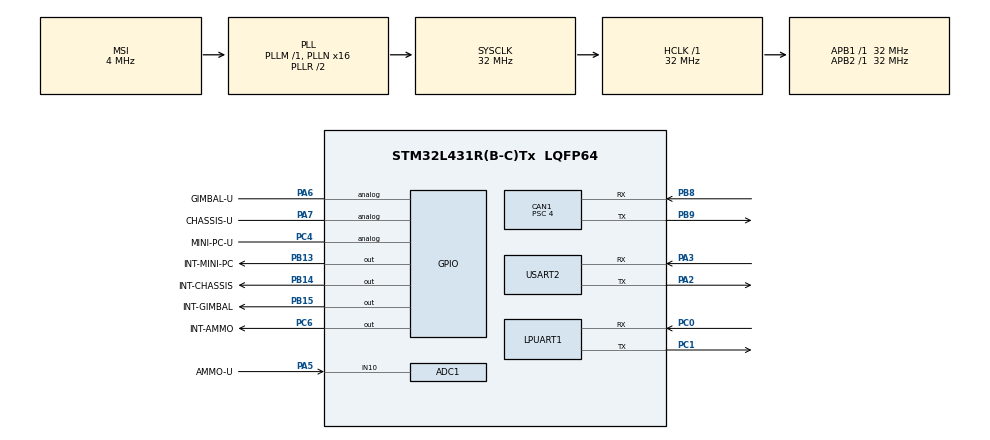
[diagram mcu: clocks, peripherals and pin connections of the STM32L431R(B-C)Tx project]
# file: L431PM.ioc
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ADC1.Channel-4\#ChannelRegularConversion=ADC_CHANNEL_10
ADC1.EOCSelection=ADC_EOC_SINGLE_CONV
ADC1.NbrOfConversionFlag=1
ADC1.OffsetNumber-4\#ChannelRegularConversion=ADC_OFFSET_NONE
ADC1.Rank-4\#ChannelRegularConversion=1
ADC1.SamplingTime-4\#ChannelRegularConversion=ADC_SAMPLETIME_47CYCLES_5
ADC1.master=1
CAN1.BS1=CAN_BS1_13TQ
CAN1.BS2=CAN_BS2_2TQ
CAN1.CalculateBaudRate=500000
CAN1.CalculateTimeBit=2000
CAN1.CalculateTimeQuantum=125.0
CAN1.Prescaler=4
Mcu.Family=STM32L4
Mcu.Name=STM32L431R(B-C)Tx
Mcu.Package=LQFP64
NVIC.ADC1_2_IRQn=true\:4\:0\:false\:false\:true\:true\:true\:true
NVIC.PriorityGroup=NVIC_PRIORITYGROUP_4
PB8.Mode=CAN_Activate
PB8.Signal=CAN1_RX
PB9.Mode=CAN_Activate
PB9.Signal=CAN1_TX
PA13\ (JTMS-SWDIO).Mode=Serial_Wire
PA13\ (JTMS-SWDIO).Signal=SYS_JTMS-SWDIO
PA14\ (JTCK-SWCLK).Mode=Serial_Wire
PA14\ (JTCK-SWCLK).Signal=SYS_JTCK-SWCLK
PA2.Mode=Asynchronous
PA2.Signal=USART2_TX
PA3.Mode=Asynchronous
PA3.Signal=USART2_RX
PA5.GPIO_Label=AMMO-U
PA5.Signal=ADCx_IN10
PA6.GPIO_Label=GIMBAL-U
PA6.Signal=GPIO_Analog
PA7.GPIO_Label=CHASSIS-U
PA7.Signal=GPIO_Analog
PB13.GPIO_Label=INT-MINI-PC
PB13.GPIO_State=GPIO_PIN_SET
PB13.Signal=GPIO_Output
PB14.GPIO_Label=INT-CHASSIS
PB14.GPIO_State=GPIO_PIN_SET
PB14.Signal=GPIO_Output
PB15.GPIO_Label=INT-GIMBAL
PB15.GPIO_State=GPIO_PIN_SET
PB15.Signal=GPIO_Output
PC0.Mode=Asynchronous
PC0.Signal=LPUART1_RX
PC1.Mode=Asynchronous
PC1.Signal=LPUART1_TX
PC4.GPIO_Label=MINI-PC-U
PC4.Signal=GPIO_Analog
PC6.GPIO_Label=INT-AMMO
PC6.Signal=GPIO_Output
PH0-OSC_IN\ (PH0).Mode=HSE-External-Oscillator
PH0-OSC_IN\ (PH0).Signal=RCC_OSC_IN
PH1-OSC_OUT\ (PH1).Mode=HSE-External-Oscillator
PH1-OSC_OUT\ (PH1).Signal=RCC_OSC_OUT
ProjectManager.HeapSize=0x200
ProjectManager.StackSize=0x400
ProjectManager.TargetToolchain=Makefile
USART2.VirtualMode-Asynchronous=VM_ASYNC
RCC.ADCFreq_Value=32000000
RCC.AHBFreq_Value=32000000
RCC.APB1Freq_Value=32000000
RCC.APB1TimFreq_Value=32000000
RCC.APB2Freq_Value=32000000
RCC.APB2TimFreq_Value=32000000
RCC.CortexFreq_Value=32000000
RCC.HCLKFreq_Value=32000000
RCC.HSE_VALUE=12000000
RCC.HSI48_VALUE=48000000
RCC.HSI_VALUE=16000000
RCC.MSI_VALUE=4000000
RCC.PLLN=16
RCC.PLLSAI1N=16
RCC.SYSCLKFreq_VALUE=32000000
RCC.SYSCLKSource=RCC_SYSCLKSOURCE_PLLCLK
RCC.VCOOutputFreq_Value=64000000
SH.ADCx_IN10.0=ADC1_IN10,IN10-Single-Ended
board=custom

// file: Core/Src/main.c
/* USER CODE BEGIN Header */
/**
  ******************************************************************************
  * @file           : main.c
  * @brief          : Main program body
  ******************************************************************************
  * @attention
  *
  * Copyright (c) 2026 STMicroelectronics.
  * All rights reserved.
  *
  * This software is licensed under terms that can be found in the LICENSE file
  * in the root directory of this software component.
  * If no LICENSE file comes with this software, it is provided AS-IS.
  *
  ******************************************************************************
  */
/* USER CODE END Header */
#include "main.h"
#include "adc.h"
#include "can.h"
#include "usart.h"
#include "gpio.h"
#include "app_power.h"
#include "app_protocol.h"
#include "app_referee_can.h"
#include "app_match.h"
#include "bsp_watchdog.h"

void SystemClock_Config(void);

int main(void)
{

  /* MCU Configuration--------------------------------------------------------*/

  /* Reset of all peripherals, Initializes the Flash interface and the Systick. */
  HAL_Init();

  /* Configure the system clock */
  SystemClock_Config();

  /* Initialize all configured peripherals */
  MX_GPIO_Init();
  MX_CAN1_Init();
  MX_LPUART1_UART_Init();
  MX_USART2_UART_Init();
  MX_ADC1_Init();
  /* USER CODE BEGIN 2 */

  (void)BSP_Watchdog_Init();
  APP_Power_Init(BSP_Watchdog_WasReset());
  APP_Protocol_Init();
  APP_RefereeCan_Init();
  APP_Match_Init();

  /* USER CODE END 2 */

  /* Infinite loop */
  while (1)
  {
    APP_Protocol_Task();
    APP_RefereeCan_Task();
    APP_Match_Task();
    BSP_Watchdog_Feed();

  }
}

void SystemClock_Config(void)
{
  RCC_OscInitTypeDef RCC_OscInitStruct = {0};
  RCC_ClkInitTypeDef RCC_ClkInitStruct = {0};

  /** Configure the main internal regulator output voltage
  */
  if (HAL_PWREx_ControlVoltageScaling(PWR_REGULATOR_VOLTAGE_SCALE1) != HAL_OK)
  {
    Error_Handler();
  }

  /** Initializes the RCC Oscillators according to the specified parameters
  * in the RCC_OscInitTypeDef structure.
  */
  RCC_OscInitStruct.OscillatorType = RCC_OSCILLATORTYPE_MSI;
  RCC_OscInitStruct.MSIState = RCC_MSI_ON;
  RCC_OscInitStruct.MSICalibrationValue = 0;
  RCC_OscInitStruct.MSIClockRange = RCC_MSIRANGE_6;
  RCC_OscInitStruct.PLL.PLLState = RCC_PLL_ON;
  RCC_OscInitStruct.PLL.PLLSource = RCC_PLLSOURCE_MSI;
  RCC_OscInitStruct.PLL.PLLM = 1;
  RCC_OscInitStruct.PLL.PLLN = 16;
  RCC_OscInitStruct.PLL.PLLP = RCC_PLLP_DIV7;
  RCC_OscInitStruct.PLL.PLLQ = RCC_PLLQ_DIV2;
  RCC_OscInitStruct.PLL.PLLR = RCC_PLLR_DIV2;
  if (HAL_RCC_OscConfig(&RCC_OscInitStruct) != HAL_OK)
  {
    Error_Handler();
  }

  /** Initializes the CPU, AHB and APB buses clocks
  */
  RCC_ClkInitStruct.ClockType = RCC_CLOCKTYPE_HCLK|RCC_CLOCKTYPE_SYSCLK
                              |RCC_CLOCKTYPE_PCLK1|RCC_CLOCKTYPE_PCLK2;
  RCC_ClkInitStruct.SYSCLKSource = RCC_SYSCLKSOURCE_PLLCLK;
  RCC_ClkInitStruct.AHBCLKDivider = RCC_SYSCLK_DIV1;
  RCC_ClkInitStruct.APB1CLKDivider = RCC_HCLK_DIV1;
  RCC_ClkInitStruct.APB2CLKDivider = RCC_HCLK_DIV1;

  if (HAL_RCC_ClockConfig(&RCC_ClkInitStruct, FLASH_LATENCY_1) != HAL_OK)
  {
    Error_Handler();
  }
}

void Error_Handler(void)
{
  __disable_irq();
  while (1)
  {
  }
}
